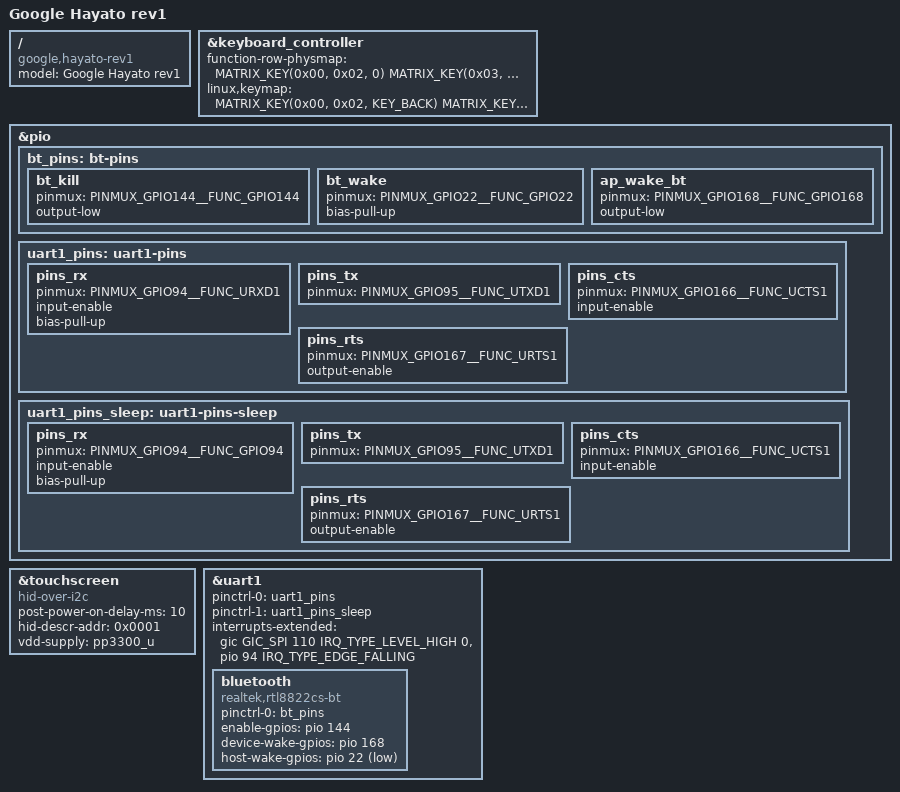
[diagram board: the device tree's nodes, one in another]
// SPDX-License-Identifier: (GPL-2.0 OR MIT)
/*
 * Copyright 2020 Google LLC
 */
/dts-v1/;
#include "mt8192-asurada.dtsi"
#include "mt8192-asurada-audio-rt1015p-rt5682.dtsi"

/ {
	model = "Google Hayato rev1";
	compatible = "google,hayato-rev1", "google,hayato", "mediatek,mt8192";
};

&keyboard_controller {
	function-row-physmap = <
		MATRIX_KEY(0x00, 0x02, 0)	/* T1 */
		MATRIX_KEY(0x03, 0x02, 0)	/* T2 */
		MATRIX_KEY(0x02, 0x02, 0)	/* T3 */
		MATRIX_KEY(0x01, 0x02, 0)	/* T4 */
		MATRIX_KEY(0x03, 0x04, 0)	/* T5 */
		MATRIX_KEY(0x02, 0x04, 0)	/* T6 */
		MATRIX_KEY(0x01, 0x04, 0)	/* T7 */
		MATRIX_KEY(0x02, 0x09, 0)	/* T8 */
		MATRIX_KEY(0x01, 0x09, 0)	/* T9 */
		MATRIX_KEY(0x00, 0x04, 0)	/* T10 */
	>;
	linux,keymap = <
		MATRIX_KEY(0x00, 0x02, KEY_BACK)
		MATRIX_KEY(0x03, 0x02, KEY_FORWARD)
		MATRIX_KEY(0x02, 0x02, KEY_REFRESH)
		MATRIX_KEY(0x01, 0x02, KEY_FULL_SCREEN)
		MATRIX_KEY(0x03, 0x04, KEY_SCALE)
		MATRIX_KEY(0x02, 0x04, KEY_BRIGHTNESSDOWN)
		MATRIX_KEY(0x01, 0x04, KEY_BRIGHTNESSUP)
		MATRIX_KEY(0x02, 0x09, KEY_MUTE)
		MATRIX_KEY(0x01, 0x09, KEY_VOLUMEDOWN)
		MATRIX_KEY(0x00, 0x04, KEY_VOLUMEUP)

		CROS_STD_MAIN_KEYMAP
	>;
};

&pio {
	bt_pins: bt-pins {
		bt_kill: bt_kill {
			pinmux = <PINMUX_GPIO144__FUNC_GPIO144>; /* BT_KILL_L */
			output-low;
		};
		bt_wake: bt_wake {
			pinmux = <PINMUX_GPIO22__FUNC_GPIO22>;  /* bt to wake ap */
			bias-pull-up;
		};
		ap_wake_bt: ap_wake_bt {
			pinmux = <PINMUX_GPIO168__FUNC_GPIO168>; /* AP_WAKE_BT_H */
			output-low;
		};
	};

	uart1_pins: uart1-pins {
		pins_rx {
			pinmux = <PINMUX_GPIO94__FUNC_URXD1>;
			input-enable;
			bias-pull-up;
		};
		pins_tx {
			pinmux = <PINMUX_GPIO95__FUNC_UTXD1>;
		};
		pins_cts {
			pinmux = <PINMUX_GPIO166__FUNC_UCTS1>;
			input-enable;
		};
		pins_rts {
			pinmux = <PINMUX_GPIO167__FUNC_URTS1>;
			output-enable;
		};
	};

	uart1_pins_sleep: uart1-pins-sleep {
		pins_rx {
			pinmux = <PINMUX_GPIO94__FUNC_GPIO94>;
			input-enable;
			bias-pull-up;
		};
		pins_tx {
			pinmux = <PINMUX_GPIO95__FUNC_UTXD1>;
		};
		pins_cts {
			pinmux = <PINMUX_GPIO166__FUNC_UCTS1>;
			input-enable;
		};
		pins_rts {
			pinmux = <PINMUX_GPIO167__FUNC_URTS1>;
			output-enable;
		};
	};
};

&touchscreen {
	compatible = "hid-over-i2c";
	post-power-on-delay-ms = <10>;
	hid-descr-addr = <0x0001>;
	vdd-supply = <&pp3300_u>;
};

&uart1 {
	status = "okay";
	pinctrl-names = "default", "sleep";
	pinctrl-0 = <&uart1_pins>;
	pinctrl-1 = <&uart1_pins_sleep>;
	interrupts-extended = <&gic GIC_SPI 110 IRQ_TYPE_LEVEL_HIGH 0>,
			      <&pio 94 IRQ_TYPE_EDGE_FALLING>;

	bluetooth: bluetooth {
		compatible = "realtek,rtl8822cs-bt";
		pinctrl-names = "default";
		pinctrl-0 = <&bt_pins>;

		enable-gpios = <&pio 144 GPIO_ACTIVE_HIGH>;
		device-wake-gpios = <&pio 168 GPIO_ACTIVE_HIGH>;
		host-wake-gpios = <&pio 22 GPIO_ACTIVE_LOW>;
	};
};
